# ISP_RESIZER register map
Vendor: Texas Instruments
Peripheral module from a debugger description file (folder omap36xx).
Registers are 32-bit, read-write, reset 0x0 unless marked. A register's access mark holds for its fields unless they carry their own. Offsets are as the file gives them; lines under a group give offsets from that group; [hi:lo] are bit positions; {n}, {i} and the like mark numbered series; 'fields as' and 'values as' point back to an identical list; <NAME> marks a mode.

## ISP_RESIZER
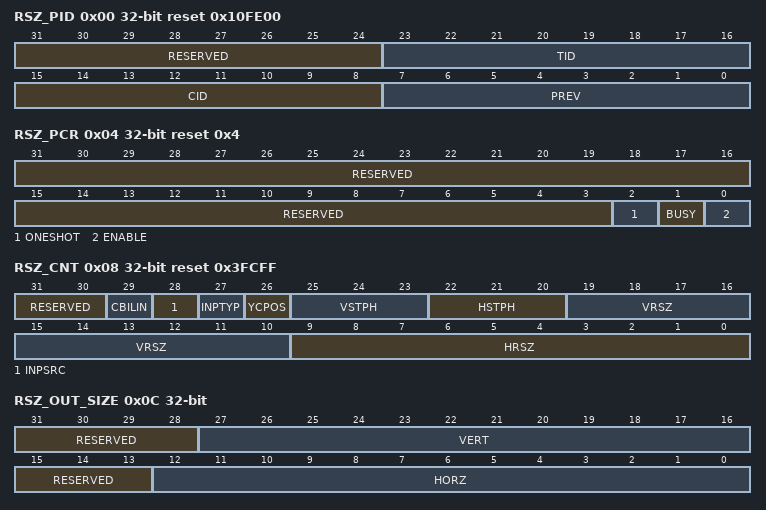
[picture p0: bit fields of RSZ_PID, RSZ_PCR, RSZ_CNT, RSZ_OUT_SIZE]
0x00 RSZ_PID ro reset 0x10FE00 (reset mask 0xFFFFFF00) — PERIPHERAL ID REGISTER
  [31:24] RESERVED — Write 0s for future compatibility. Reads returns 0.
  [23:16] TID — Peripheral identification: RESIZER module
  [15:8] CID — Class identification: Camera ISP
  [7:0] PREV — Peripheral revision number
0x04 RSZ_PCR access per field reset 0x4 — PERIPHERAL CONTROL REGISTER
  [31:3] RESERVED rw — Write 0s for future compatibility.Reads returns 0.
  [2] ONESHOT rw — One-shot or continuous mode selection.This bit only applies when the image source is CCDC or PREVIEW (RSZ_CNT INPSRC =0)
    0=Continuous mode. The module must be disabled by software. The disable module is latched at the end of the frame it was written in.; 1=One shot mode. Enable bit is reset to 0 once the busy bit turns to 1.
  [1] BUSY ro — RESIZER module busy.
    0=RESIZER module not busy; 1=RESIZER module busy
  [0] ENABLE rw — RESIZER module enable.Memory to memory operation: Resizer always operates in one-shot mode in memory to memory operation. Enable bit is reset to 0 once the busy bit turns to 1.CCDC/PREVIEW to memory operation: The resizer operates either in one-shot or continuous mode. The behavior is defined by the RSZ_PCR [2] ONESHOT bit.The enable bit MUST be the last field written to resize a frame. The enable bit can be written when the resizer is busy.
    0=Disable RESIZER module; 1=Enable RESIZER module
0x08 RSZ_CNT reset 0x3FCFF — RESIZER CONTROL REGISTER
  [31:30] RESERVED — Write 0s for future compatibility.Reads returns 0.
  [29] CBILIN — Chrominance horizontal algorithm select.Filtering that is same as luminance processing is intended only for downsampling, and bilinear interpolation is intended only for upsampling.
    0=The chrominance uses the same processing as the luminance; 1=The chrominance uses bilinear interpolation processing
  [28] INPSRC — Input source select.NOTE: If this field is set to zero, the resizer input is fed from either the preview engine or the CCDC, but not both. The CCDC and preview engine modules have individual control to feed their output to the resizer input. If both the CCDC and preview engine modules are set to drive the resizer input, the CCDC output takes precedence.
    0=PREVIEW or CCDC module; 1=Memory
  [27] INPTYP — Input type select.
    0=YUV422 color is interleaved; 1=Color separate data on 8 bits
  [26] YCPOS — Luminance and chrominance position in 16-bit word
    0=YC; 1=CY
  [25:23] VSTPH — Vertical starting phase. The phase range is 0 to 7.
  [22:20] HSTPH — Horizontal starting phase. The phase range is 0 to 7.
  [19:10] VRSZ — Vertical resizing value. (range from 64 - 1024) plus 1Vertical resizing ratio is 256/(VRSZ+1)For have the correct functionality, must enter the desired value minus 1. For example for a ratio of 1, must enter 255
  [9:0] HRSZ — Horizontal resizing value. (range from 64 - 1024) plus 1Horizontal resizing ratio is 256/(HRSZ+1) For have the correct functionality, must enter the desired value minus 1. For example for a ratio of 1, must enter 255
0x0C RSZ_OUT_SIZE — OUTPUT SIZE REGISTER
  [31:28] RESERVED — Write 0s for future compatibility.Reads returns 0.
  [27:16] VERT — Output height.
  [15:13] RESERVED — Write 0s for future compatibility.Reads returns 0.
  [12:0] HORZ — Output (width in the horizontal direction)The maximum output width cannot be greater than 4096 pixels wide (2048 if downsampling greater than 2 is used with 7 filter taps) This value must be EVEN and the number of bytes written to SDRAM must be a multiple of 16-bytes if the vertical resizing factor is greater than 1x (upsizing)
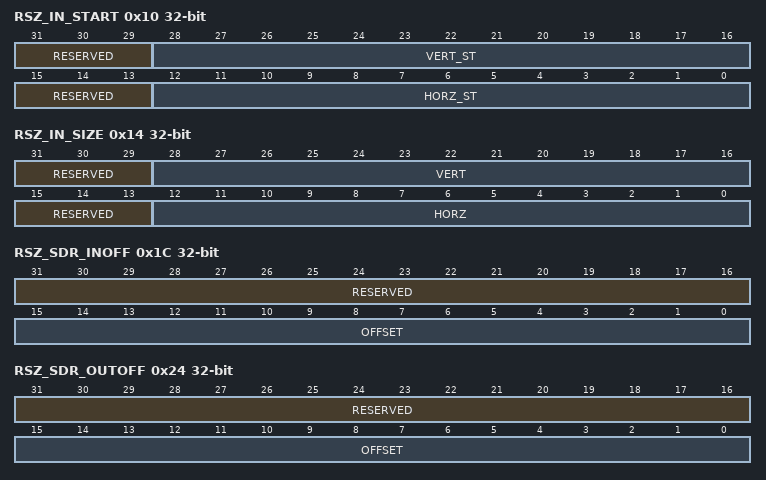
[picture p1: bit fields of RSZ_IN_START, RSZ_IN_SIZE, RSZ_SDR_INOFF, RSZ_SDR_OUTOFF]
0x10 RSZ_IN_START — INPUT CONFIGURATION REGISTER This register must be used when the input pixel data comes from the PREVIEW module. must be set to 0 is the input pixel data comes from memory.
  [31:29] RESERVED — Write 0s for future compatibility.Reads returns 0.
  [28:16] VERT_ST — Vertical start line.This field makes sense when the resizer obtains its input from the preview engine/CCDC When the resizer gets its input from SDRAM, this field must be set to 0
  [15:13] RESERVED — Write 0s for future compatibility.Reads returns 0.
  [12:0] HORZ_ST — Horizontal start pixel. Pixels are coded on 16 bits for YUV and 8 bits for color separate data. When the resizer gets its input from SDRAM, this field must be set to = 15 for YUV 16-bit data and = 31 for 8-bit color separate data Horizontal starting pixel value is in number of pixels if input is from SDRAM. If the input to the resizer is from CCDC/preview engine, this field must be programmed as follows:(1) Program this field using number of bytes (twice number of pixels).(2) Change the lowest bit to reflect start position in pixels (effectively change from a value 0 to a value 1 if required)
0x14 RSZ_IN_SIZE — INPUT SIZE REGISTER
  [31:29] RESERVED — Write 0s for future compatibility.Reads returns 0.
  [28:16] VERT — Input height. The range is 0 to 4095 lines.
  [15:13] RESERVED — Write 0s for future compatibility.Reads returns 0.
  [12:0] HORZ — Input width. The range is 0 to 4095 pixels.
0x18 RSZ_SDR_INADD — INPUT ADDRESS REGISTER This register must be set only if the input pixel data comes from memory.
  [31:0] ADDR — 32-bit input memory address. The 5 LSBs are forced to be zeros by the hardware to align on a 32-byte boundary; the 5 LSBs are read-only. This field must be programmed to be 0x0 if the resizer input is from preview engine/CCDC. * This field can be altered even when the resizer is busy. The change takes place only for the next frame. However, note that reading this register always gives the latest value.
0x1C RSZ_SDR_INOFF — INPUT OFFSET REGISTER This register must be set only if the input pixel data comes from memory.
  [31:16] RESERVED — Write 0s for future compatibility.Reads returns 0.
  [15:0] OFFSET — Memory offset for the input lines. The 5 LSBs are forced to be zeros by the hardware to align on a 32-byte boundary; the 5 LSBs are read-only. This field must be programmed to be 0x0 if the resizer input is from preview engine/CCDC. * This field can be altered even when the resizer is busy. The change takes place only for the next frame. However, note that reading this register always gives the latest value.
0x20 RSZ_SDR_OUTADD — OUTPUT ADDRESS REGISTER
  [31:0] ADDR — 32-bit output memory address. The 5 LSBs are forced to be zeros by the hardware to align on a 32-byte boundary; the 5 LSBs are read-only. For optimal use of SDRAM bandwidth, the SDRAM address must be set on a 256-byte boundary * This field can be altered even when the resizer is busy. The change takes place only for the next frame. However, note that reading this register always gives the latest value.
0x24 RSZ_SDR_OUTOFF — OUTPUT OFFSET REGISTER
  [31:16] RESERVED — Write 0s for future compatibility.Reads returns 0.
  [15:0] OFFSET — Memory offset for the output lines. The 5 LSBs are forced to be zeros by the hardware to align on a 32-byte boundary; the 5 LSBs are read-only. For optimal use of SDRAM bandwidth, the SDRAM line offset must be set on a 256-byte boundary. * This field can be altered even when the resizer is busy. The change takes place only for the next frame. However, note that reading this register always gives the latest value.
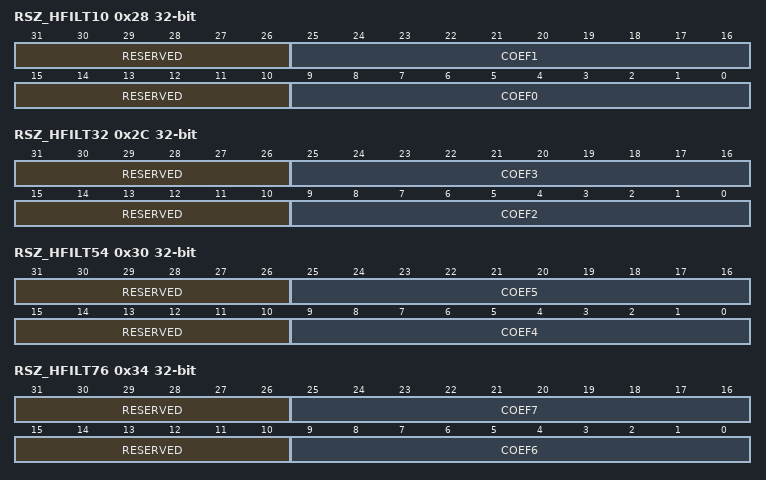
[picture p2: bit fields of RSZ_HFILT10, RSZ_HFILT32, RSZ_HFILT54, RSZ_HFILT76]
0x28 RSZ_HFILT10 — HORIZONTAL FILTER COEFFICIENTS 0 AND 1 REGISTER
  [31:26] RESERVED — Write 0s for future compatibility.Reads returns 0.
  [25:16] COEF1 — 10-bit coefficient (S10Q8 format - range of -2 to 1.255/256, 1 is 0x100) - Phase 0, tap 1
  [15:10] RESERVED — Write 0s for future compatibility.Reads returns 0.
  [9:0] COEF0 — 10-bit coefficient (S10Q8 format - range of -2 to 1.255/256, 1 is 0x100) - Phase 0, tap 0
0x2C RSZ_HFILT32 — HORIZONTAL FILTER COEFFICIENTS 2 AND 3 REGISTER
  [31:26] RESERVED — Write 0s for future compatibility.Reads returns 0.
  [25:16] COEF3 — 10-bit coefficient (S10Q8 format - range of -2 to 1.255/256, 1 is 0x100) - Phase 0, tap 3
  [15:10] RESERVED — Write 0s for future compatibility.Reads returns 0.
  [9:0] COEF2 — 10-bit coefficient (S10Q8 format - range of -2 to 1.255/256, 1 is 0x100) - Phase 0, tap 2
0x30 RSZ_HFILT54 — HORIZONTAL FILTER COEFFICIENTS 4 AND 5 REGISTER
  [31:26] RESERVED — Write 0s for future compatibility.Reads returns 0.
  [25:16] COEF5 — 10-bit coefficient (S10Q8 format - range of -2 to 1.255/256, 1 is 0x100) - Phase 0/1, tap 5/1
  [15:10] RESERVED — Write 0s for future compatibility.Reads returns 0.
  [9:0] COEF4 — 10-bit coefficient (S10Q8 format - range of -2 to 1.255/256, 1 is 0x100) - Phase 0/1, tap 4/0
0x34 RSZ_HFILT76 — HORIZONTAL FILTER COEFFICIENTS 6 AND 37REGISTER
  [31:26] RESERVED — Write 0s for future compatibility.Reads returns 0.
  [25:16] COEF7 — 10-bit coefficient (S10Q8 format - range of -2 to 1.255/256, 1 is 0x100) - Phase 0/1, tap 7/3
  [15:10] RESERVED — Write 0s for future compatibility.Reads returns 0.
  [9:0] COEF6 — 10-bit coefficient (S10Q8 format - range of -2 to 1.255/256, 1 is 0x100) - Phase 0/1, tap 6/2
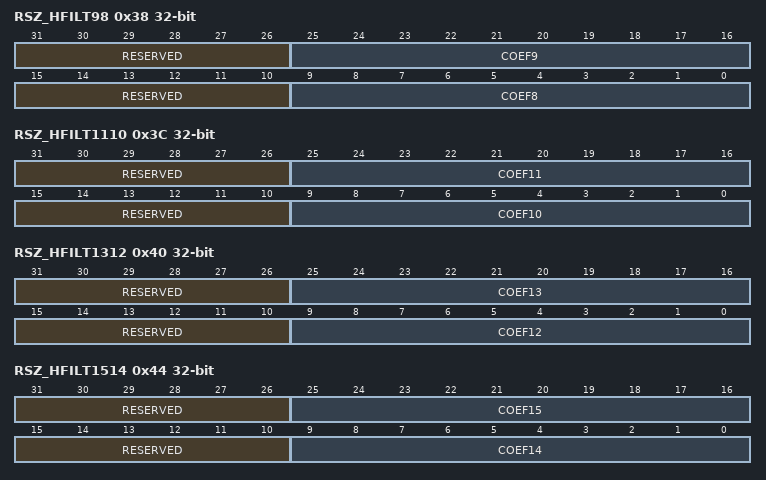
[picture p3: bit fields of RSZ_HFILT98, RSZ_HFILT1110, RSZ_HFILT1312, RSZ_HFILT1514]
0x38 RSZ_HFILT98 — HORIZONTAL FILTER COEFFICIENTS 8 AND 9 REGISTER
  [31:26] RESERVED — Write 0s for future compatibility.Reads returns 0.
  [25:16] COEF9 — 10-bit coefficient (S10Q8 format - range of -2 to 1.255/256, 1 is 0x100) - Phase 1/2, tap 1/1
  [15:10] RESERVED — Write 0s for future compatibility.Reads returns 0.
  [9:0] COEF8 — 10-bit coefficient (S10Q8 format - range of -2 to 1.255/256, 1 is 0x100) - Phase 1/2, tap 0/0
0x3C RSZ_HFILT1110 — HORIZONTAL FILTER COEFFICIENTS 10 AND 11 REGISTER
  [31:26] RESERVED — Write 0s for future compatibility.Reads returns 0.
  [25:16] COEF11 — 10-bit coefficient (S10Q8 format - range of -2 to 1.255/256, 1 is 0x100) - Phase 1/2, tap 3/3
  [15:10] RESERVED — Write 0s for future compatibility.Reads returns 0.
  [9:0] COEF10 — 10-bit coefficient (S10Q8 format - range of -2 to 1.255/256, 1 is 0x100) - Phase 1/2, tap 2/2
0x40 RSZ_HFILT1312 — HORIZONTAL FILTER COEFFICIENTS 12 AND 13 REGISTER
  [31:26] RESERVED — Write 0s for future compatibility.Reads returns 0.
  [25:16] COEF13 — 10-bit coefficient (S10Q8 format - range of -2 to 1.255/256, 1 is 0x100) - Phase 1/3, tap 5/1
  [15:10] RESERVED — Write 0s for future compatibility.Reads returns 0.
  [9:0] COEF12 — 10-bit coefficient (S10Q8 format - range of -2 to 1.255/256, 1 is 0x100) - Phase 1/3, tap 4/0
0x44 RSZ_HFILT1514 — HORIZONTAL FILTER COEFFICIENTS 14 AND 15 REGISTER
  [31:26] RESERVED — Write 0s for future compatibility.Reads returns 0.
  [25:16] COEF15 — 10-bit coefficient (S10Q8 format - range of -2 to 1.255/256, 1 is 0x100) - Phase 1/3, tap 7/3
  [15:10] RESERVED — Write 0s for future compatibility.Reads returns 0.
  [9:0] COEF14 — 10-bit coefficient (S10Q8 format - range of -2 to 1.255/256, 1 is 0x100) - Phase 1/3, tap 6/2
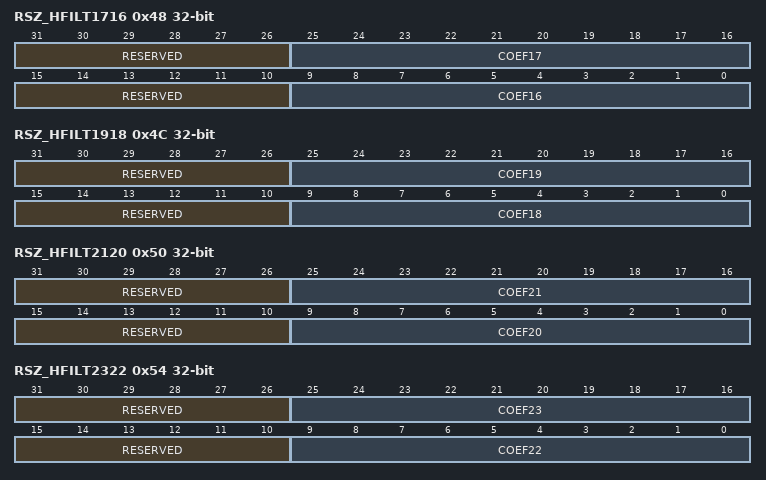
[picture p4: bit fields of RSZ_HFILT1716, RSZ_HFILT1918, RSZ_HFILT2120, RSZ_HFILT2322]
0x48 RSZ_HFILT1716 — HORIZONTAL FILTER COEFFICIENTS 17 AND 16 REGISTER
  [31:26] RESERVED — Write 0s for future compatibility.Reads returns 0.
  [25:16] COEF17 — 10-bit coefficient (S10Q8 format - range of -2 to 1.255/256, 1 is 0x100) - Phase 2/4, tap 1/1
  [15:10] RESERVED — Write 0s for future compatibility.Reads returns 0.
  [9:0] COEF16 — 10-bit coefficient (S10Q8 format - range of -2 to 1.255/256, 1 is 0x100) - Phase 2/4, tap 0/0
0x4C RSZ_HFILT1918 — HORIZONTAL FILTER COEFFICIENTS 18 AND 19 REGISTER
  [31:26] RESERVED — Write 0s for future compatibility.Reads returns 0.
  [25:16] COEF19 — 10-bit coefficient (S10Q8 format - range of -2 to 1.255/256, 1 is 0x100) - Phase 2/4, tap 3/3
  [15:10] RESERVED — Write 0s for future compatibility.Reads returns 0.
  [9:0] COEF18 — 10-bit coefficient (S10Q8 format - range of -2 to 1.255/256, 1 is 0x100) - Phase 2/4, tap 2/2
0x50 RSZ_HFILT2120 — HORIZONTAL FILTER COEFFICIENTS 20 AND 21 REGISTER
  [31:26] RESERVED — Write 0s for future compatibility.Reads returns 0.
  [25:16] COEF21 — 10-bit coefficient (S10Q8 format - range of -2 to 1.255/256, 1 is 0x100) - Phase 2/5, tap 5/1
  [15:10] RESERVED — Write 0s for future compatibility.Reads returns 0.
  [9:0] COEF20 — 10-bit coefficient (S10Q8 format - range of -2 to 1.255/256, 1 is 0x100) - Phase 2/5, tap 4/0
0x54 RSZ_HFILT2322 — HORIZONTAL FILTER COEFFICIENTS 22 AND 23 REGISTER
  [31:26] RESERVED — Write 0s for future compatibility.Reads returns 0.
  [25:16] COEF23 — 10-bit coefficient (S10Q8 format - range of -2 to 1.255/256, 1 is 0x100) - Phase 2/5, tap 7/3
  [15:10] RESERVED — Write 0s for future compatibility.Reads returns 0.
  [9:0] COEF22 — 10-bit coefficient (S10Q8 format - range of -2 to 1.255/256, 1 is 0x100) - Phase 2/5, tap 6/2
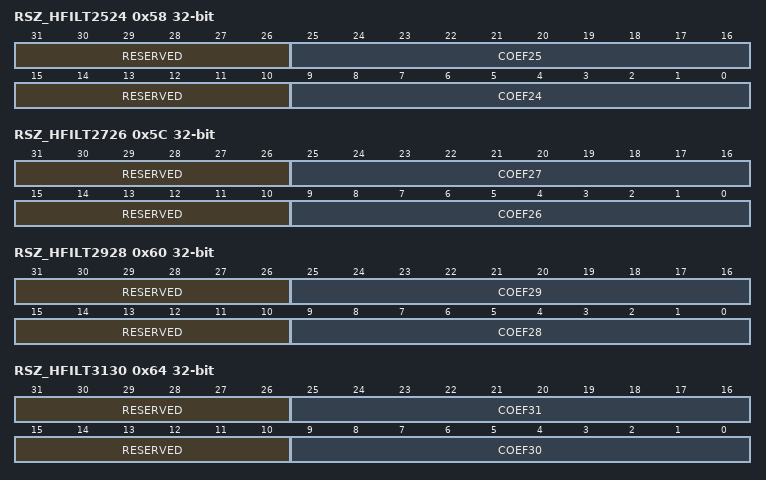
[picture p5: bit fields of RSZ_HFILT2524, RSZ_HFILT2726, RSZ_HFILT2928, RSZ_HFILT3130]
0x58 RSZ_HFILT2524 — HORIZONTAL FILTER COEFFICIENTS 24 AND 25 REGISTER
  [31:26] RESERVED — Write 0s for future compatibility.Reads returns 0.
  [25:16] COEF25 — 10-bit coefficient (S10Q8 format - range of -2 to 1.255/256, 1 is 0x100) - Phase 3/6, tap 1/1
  [15:10] RESERVED — Write 0s for future compatibility.Reads returns 0.
  [9:0] COEF24 — 10-bit coefficient (S10Q8 format - range of -2 to 1.255/256, 1 is 0x100) - Phase 3/6, tap 0/0
0x5C RSZ_HFILT2726 — HORIZONTAL FILTER COEFFICIENTS 26 AND 27 REGISTER
  [31:26] RESERVED — Write 0s for future compatibility.Reads returns 0.
  [25:16] COEF27 — 10-bit coefficient (S10Q8 format - range of -2 to 1.255/256, 1 is 0x100) - Phase 3/6, tap 3/3
  [15:10] RESERVED — Write 0s for future compatibility.Reads returns 0.
  [9:0] COEF26 — 10-bit coefficient (S10Q8 format - range of -2 to 1.255/256, 1 is 0x100) - Phase 3/6, tap 2/2
0x60 RSZ_HFILT2928 — HORIZONTAL FILTER COEFFICIENTS 28 AND 29 REGISTER
  [31:26] RESERVED — Write 0s for future compatibility.Reads returns 0.
  [25:16] COEF29 — 10-bit coefficient (S10Q8 format - range of -2 to 1.255/256, 1 is 0x100) - Phase 3/7, tap 5/1
  [15:10] RESERVED — Write 0s for future compatibility.Reads returns 0.
  [9:0] COEF28 — 10-bit coefficient (S10Q8 format - range of -2 to 1.255/256, 1 is 0x100) - Phase 3/7, tap 4/0
0x64 RSZ_HFILT3130 — HORIZONTAL FILTER COEFFICIENTS 30 AND 31 REGISTER
  [31:26] RESERVED — Write 0s for future compatibility.Reads returns 0.
  [25:16] COEF31 — 10-bit coefficient (S10Q8 format - range of -2 to 1.255/256, 1 is 0x100) - Phase 3/7, tap 7/3
  [15:10] RESERVED — Write 0s for future compatibility.Reads returns 0.
  [9:0] COEF30 — 10-bit coefficient (S10Q8 format - range of -2 to 1.255/256, 1 is 0x100) - Phase 3/7, tap 6/2
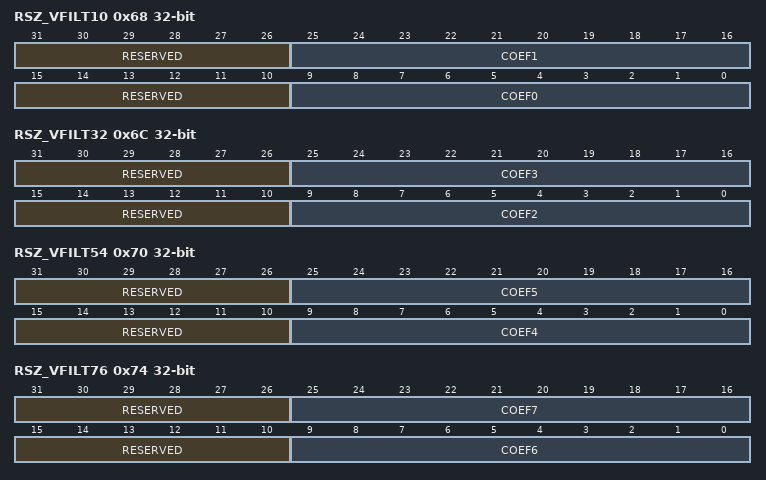
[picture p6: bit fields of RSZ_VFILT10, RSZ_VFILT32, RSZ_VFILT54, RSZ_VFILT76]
0x68 RSZ_VFILT10 — VERTICAL FILTER COEFFICIENTS 0 AND 1 REGISTER
  fields as RSZ_HFILT10
0x6C RSZ_VFILT32 — VERTICAL FILTER COEFFICIENTS 2 AND 3 REGISTER
  fields as RSZ_HFILT32
0x70 RSZ_VFILT54 — VERTICAL FILTER COEFFICIENTS 4 AND 5 REGISTER
  fields as RSZ_HFILT54
0x74 RSZ_VFILT76 — VERTICAL FILTER COEFFICIENTS 6 AND 7 REGISTER
  fields as RSZ_HFILT76
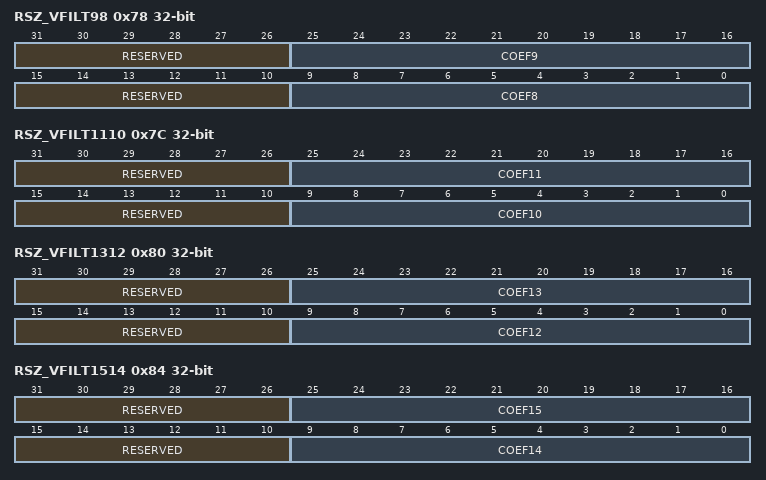
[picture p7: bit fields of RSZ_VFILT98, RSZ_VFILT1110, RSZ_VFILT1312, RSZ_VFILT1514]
0x78 RSZ_VFILT98 — VERTICAL FILTER COEFFICIENTS 8 AND 9 REGISTER
  fields as RSZ_HFILT98
0x7C RSZ_VFILT1110 — VERTICAL FILTER COEFFICIENTS 10 AND 11 REGISTER
  fields as RSZ_HFILT1110
0x80 RSZ_VFILT1312 — VERTICAL FILTER COEFFICIENTS 12 AND 13 REGISTER
  fields as RSZ_HFILT1312
0x84 RSZ_VFILT1514 — VERTICAL FILTER COEFFICIENTS 14 AND 15 REGISTER
  fields as RSZ_HFILT1514
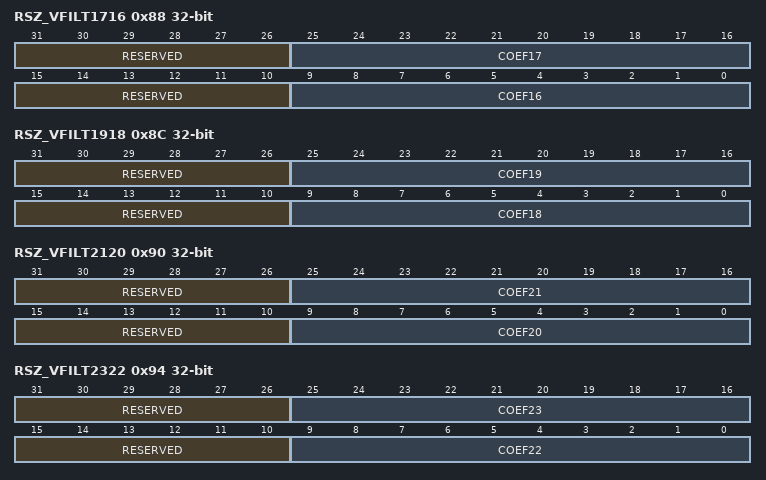
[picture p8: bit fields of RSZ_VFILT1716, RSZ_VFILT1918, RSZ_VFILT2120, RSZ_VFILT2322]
0x88 RSZ_VFILT1716 — VERTICAL FILTER COEFFICIENTS 16 AND 17 REGISTER
  fields as RSZ_HFILT1716
0x8C RSZ_VFILT1918 — VERTICAL FILTER COEFFICIENTS 18 AND 19 REGISTER
  fields as RSZ_HFILT1918
0x90 RSZ_VFILT2120 — VERTICAL FILTER COEFFICIENTS 20 AND 21 REGISTER
  fields as RSZ_HFILT2120
0x94 RSZ_VFILT2322 — VERTICAL FILTER COEFFICIENTS 22 AND 23 REGISTER
  fields as RSZ_HFILT2322
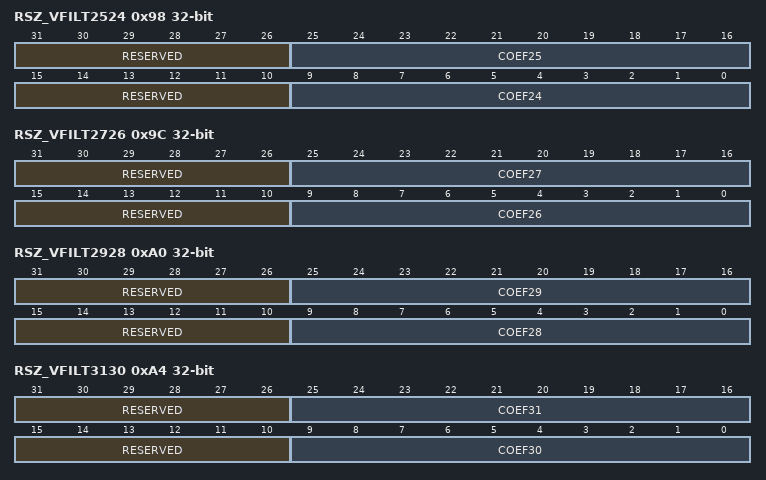
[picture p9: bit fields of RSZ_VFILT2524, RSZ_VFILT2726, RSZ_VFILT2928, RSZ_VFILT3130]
0x98 RSZ_VFILT2524 — VERTICAL FILTER COEFFICIENTS 24 AND 25 REGISTER
  fields as RSZ_HFILT2524
0x9C RSZ_VFILT2726 — VERTICAL FILTER COEFFICIENTS 26 AND 27 REGISTER
  fields as RSZ_HFILT2726
0xA0 RSZ_VFILT2928 — VERTICAL FILTER COEFFICIENTS 28 AND 29 REGISTER
  fields as RSZ_HFILT2928
0xA4 RSZ_VFILT3130 — VERTICAL FILTER COEFFICIENTS 30 AND 31 REGISTER
  fields as RSZ_HFILT3130
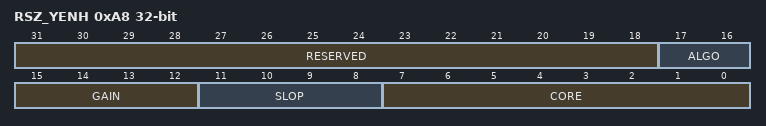
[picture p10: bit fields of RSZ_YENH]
0xA8 RSZ_YENH — LUMINANCE ENHANCER REGISTER The new luminance value is computed as: Y += HPF(Y) x max(GAIN, (|HPF(Y) - CORE) x SLOP + 8) 4.
  [31:18] RESERVED — Write 0s for future compatibility.Reads returns 0.
  [17:16] ALGO — Algorithm select.
    0=Disable; 1=[-1 2 -1]/2 high-pass filter; 2=[-1 -2 6 -2 -1]/4 high-pass filter
  [15:12] GAIN — Maximum gain. The data is coded in U4Q4 representation.
  [11:8] SLOP — Slope. The data is coded in U4Q4 representation.
  [7:0] CORE — Coring offset. The data is coded in U8Q0 representation.
